AUTOSAR XML (schema 4-2-2)
package /ComponentTypes
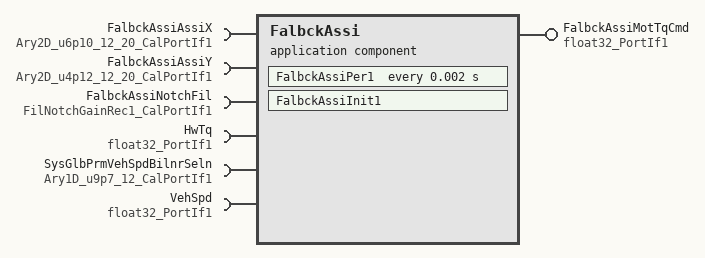
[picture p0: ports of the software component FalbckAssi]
  application sw component type FalbckAssi
    provide port FalbckAssiMotTqCmd: nonqueued-sender-com-spec{data-element=Val, init-value=0}, provided-interface=float32_PortIf1
    6 x require port:
      FalbckAssiAssiX: parameter-require-com-spec{init-value=[[0, 4, 508, 608, 712, 816, 916, 1020, 1124, 1228, 1328, 1432, 1536, 1636, 1740, 1844, 1944, 2048, 6920, 10240], [0, 204, 716, 792, 868, 944, 1016, 1092, 1168, 1244, 1316, 1392, 1468, 1544, 1616, 1692, 1768, 1844, 9348, 10240], [0, 308, 820, 908, 1000, 1088, 1176, 1268, 1356, 1448, 1536, 1624, 1716, 1804, 1896, 1984, 2072, 2164, 2252, 10240], [0, 192, 1024, 1164, 1304, 1448, 1588, 1728, 1868, 2008, 2152, 2292, 2432, 2572, 2712, 2856, 2996, 3136, 3276, 10240], [0, 176, 836, 1048, 1260, 1472, 1684, 1896, 2108, 2320, 2532, 2744, 2956, 3168, 3380, 3592, 3804, 4016, 4228, 10240], [0, 192, 916, 1148, 1376, 1608, 1840, 2072, 2304, 2536, 2768, 3000, 3232, 3464, 3692, 3924, 4156, 4388, 4620, 10240], [0, 204, 972, 1220, 1464, 1712, 1960, 2204, 2452, 2696, 2944, 3192, 3436, 3684, 3928, 4176, 4424, 4668, 4916, 10240], [0, 216, 1020, 1280, 1540, 1796, 2056, 2316, 2572, 2832, 3092, 3348, 3608, 3868, 4128, 4384, 4644, 4904, 5160, 10240], [0, 244, 1168, 1464, 1760, 2056, 2352, 2644, 2940, 3236, 3532, 3828, 4124, 4420, 4716, 5012, 5308, 5604, 5900, 10240], [0, 308, 1460, 1828, 2200, 2568, 2936, 3308, 3676, 4048, 4416, 4784, 5156, 5524, 5896, 6264, 6632, 7004, 7372, 10240], [0, 4, 1892, 2140, 2596, 2880, 3396, 3640, 4436, 4676, 5200, 5712, 6220, 6748, 7268, 7512, 8024, 8552, 8800, 10240], [0, 4, 1892, 2140, 2596, 2880, 3396, 3640, 4436, 4676, 5200, 5712, 6220, 6748, 7268, 7512, 8024, 8552, 8800, 10240]], parameter=Ary2D}, required-interface=Ary2D_u6p10_12_20_CalPortIf1
      FalbckAssiAssiY: parameter-require-com-spec{init-value=[[0, 0, 40, 58, 98, 159, 242, 343, 470, 615, 782, 972, 1182, 1411, 1663, 1937, 2232, 2546, 18022, 18022], [0, 0, 41, 52, 73, 107, 150, 205, 270, 346, 432, 530, 637, 756, 885, 1025, 1176, 1338, 18022, 18022], [0, 0, 29, 37, 55, 86, 122, 171, 229, 294, 372, 458, 551, 655, 770, 894, 1027, 1169, 1321, 15274], [0, 0, 41, 55, 79, 121, 171, 239, 317, 409, 513, 630, 759, 904, 1059, 1230, 1413, 1607, 1815, 12432], [0, 0, 49, 73, 113, 171, 245, 340, 447, 574, 716, 879, 1053, 1249, 1460, 1688, 1933, 2196, 2473, 10636], [0, 0, 49, 73, 113, 171, 245, 340, 447, 574, 716, 879, 1053, 1249, 1460, 1688, 1933, 2196, 2473, 9452], [0, 0, 49, 73, 113, 171, 245, 340, 447, 574, 716, 879, 1053, 1249, 1460, 1688, 1933, 2196, 2473, 8691], [0, 0, 49, 73, 113, 171, 245, 340, 447, 574, 716, 879, 1053, 1249, 1460, 1688, 1933, 2196, 2473, 8122], [0, 0, 49, 73, 113, 171, 245, 340, 447, 574, 716, 879, 1053, 1249, 1460, 1688, 1933, 2196, 2473, 6697], [0, 0, 49, 73, 113, 171, 245, 340, 447, 574, 716, 879, 1053, 1249, 1460, 1688, 1933, 2196, 2473, 4706], [0, 0, 66, 84, 131, 168, 254, 300, 488, 554, 713, 892, 1090, 1315, 1559, 1681, 1953, 2253, 2404, 3267], [0, 0, 66, 84, 131, 168, 254, 300, 488, 554, 713, 892, 1090, 1315, 1559, 1681, 1953, 2253, 2404, 3267]], parameter=Ary2D}, required-interface=Ary2D_u4p12_12_20_CalPortIf1
      FalbckAssiNotchFil: parameter-require-com-spec{init-value=fields=[FilGainB0:2.6297, FilGainB1:-4.75311, FilGainB2:2.20752, FilGainA1:-0.2362, FilGainA2:-0.6796], parameter=Rec}, required-interface=FilNotchGainRec1_CalPortIf1
      HwTq: nonqueued-receiver-com-spec{data-element=Val, filter=data-filter-type=ALWAYS, init-value=0}, required-interface=float32_PortIf1
      SysGlbPrmVehSpdBilnrSeln: parameter-require-com-spec{init-value=[0, 640, 1920, 3840, 7680, 10240, 12800, 15360, 19200, 23040, 25600, 28160], parameter=Ary1D}, required-interface=Ary1D_u9p7_12_CalPortIf1
      VehSpd: nonqueued-receiver-com-spec{data-element=Val, filter=data-filter-type=ALWAYS, init-value=0}, required-interface=float32_PortIf1
    behavior FalbckAssi_InternalBehavior
      ar-typed-per-instance-memorys:
        data FalbckAssiNotchFil1: sw-calibration-access=READ-ONLY, type=float32
        data FalbckAssiNotchFil2: sw-calibration-access=READ-ONLY, type=float32
      init event FalbckAssi_InitEvent: start-on-event=FalbckAssiInit1
      timing event TMT_FalbckAssiPer1: start-on-event=FalbckAssiPer1, period=0.002
      port-api-options:
        enable-take-address=false, error-handling=NO-TRANSFORMER-ERROR-HANDLING, indirect-api=false, port=FalbckAssiAssiX
        enable-take-address=false, error-handling=NO-TRANSFORMER-ERROR-HANDLING, indirect-api=false, port=FalbckAssiAssiY
        enable-take-address=false, error-handling=NO-TRANSFORMER-ERROR-HANDLING, indirect-api=false, port=FalbckAssiMotTqCmd
        enable-take-address=false, error-handling=NO-TRANSFORMER-ERROR-HANDLING, indirect-api=false, port=FalbckAssiNotchFil
        enable-take-address=false, error-handling=NO-TRANSFORMER-ERROR-HANDLING, indirect-api=false, port=HwTq
        enable-take-address=false, error-handling=NO-TRANSFORMER-ERROR-HANDLING, indirect-api=false, port=SysGlbPrmVehSpdBilnrSeln
        enable-take-address=false, error-handling=NO-TRANSFORMER-ERROR-HANDLING, indirect-api=false, port=VehSpd
      runnable FalbckAssiInit1
      runnable FalbckAssiPer1
        data-receive-point-by-arguments:
          access REC_HwTq_Val: accessed-variable=HwTq.Val
          access REC_VehSpd_Val: accessed-variable=VehSpd.Val
        data-send-points:
          access SEND_FalbckAssiMotTqCmd_Val: accessed-variable=FalbckAssiMotTqCmd.Val
  swc implementation FalbckAssi_Implementation: behavior=FalbckAssi_InternalBehavior
    code-descriptors:
      code Default: artifact-descriptors=autosar-engineering-object={short-label=Default, category=SWSRC}
